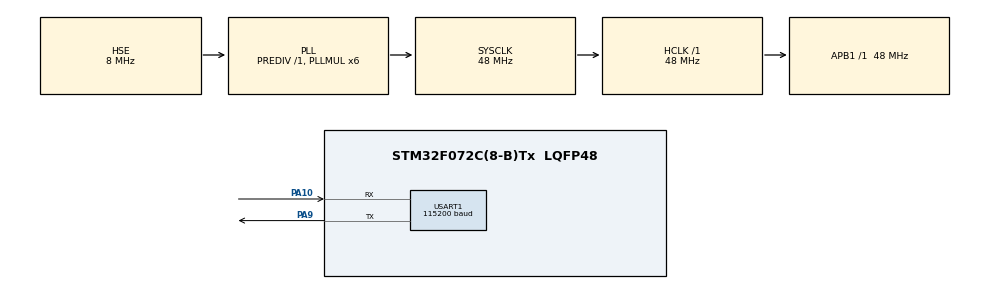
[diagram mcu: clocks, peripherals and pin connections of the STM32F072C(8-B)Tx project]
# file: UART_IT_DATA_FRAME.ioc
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Mcu.Family=STM32F0
Mcu.Name=STM32F072C(8-B)Tx
Mcu.Package=LQFP48
NVIC.USART1_IRQn=true\:0\:0\:false\:false\:true\:true\:true\:true
PA10.Mode=Asynchronous
PA10.Signal=USART1_RX
PA13.Mode=Serial_Wire
PA13.Signal=SYS_SWDIO
PA14.Mode=Serial_Wire
PA14.Signal=SYS_SWCLK
PA9.Mode=Asynchronous
PA9.Signal=USART1_TX
PF0-OSC_IN.Mode=HSE-External-Oscillator
PF0-OSC_IN.Signal=RCC_OSC_IN
PF1-OSC_OUT.Mode=HSE-External-Oscillator
PF1-OSC_OUT.Signal=RCC_OSC_OUT
ProjectManager.HeapSize=0x200
ProjectManager.StackSize=0x400
ProjectManager.TargetToolchain=MDK-ARM V5.32
RCC.AHBFreq_Value=48000000
RCC.APB1Freq_Value=48000000
RCC.APB1TimFreq_Value=48000000
RCC.HCLKFreq_Value=48000000
RCC.PLLMUL=RCC_PLL_MUL6
RCC.PLLSourceVirtual=RCC_PLLSOURCE_HSE
RCC.SYSCLKFreq_VALUE=48000000
RCC.SYSCLKSource=RCC_SYSCLKSOURCE_PLLCLK
USART1.BaudRate=115200
USART1.VirtualMode-Asynchronous=VM_ASYNC
board=custom

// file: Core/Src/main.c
/* USER CODE BEGIN Header */
/**
  ******************************************************************************
  * @file           : main.c
  * @brief          : Main program body
  ******************************************************************************
  * @attention
  *
  * Copyright (c) 2024 STMicroelectronics.
  * All rights reserved.
  *
  * This software is licensed under terms that can be found in the LICENSE file
  * in the root directory of this software component.
  * If no LICENSE file comes with this software, it is provided AS-IS.
  *
  ******************************************************************************
  */
/* USER CODE END Header */
#include "main.h"
#include "usart.h"
#include "gpio.h"

/* USER CODE BEGIN PV */
uint8_t uart_rx_buff[256];
uint8_t uart_tx_buff[256];
uint8_t recevie_byte = 0;
uint8_t receive_flag = 0;
uint8_t receive_index = 0;
/* USER CODE END PV */

void SystemClock_Config(void);

int main(void)
{

  /* MCU Configuration--------------------------------------------------------*/

  /* Reset of all peripherals, Initializes the Flash interface and the Systick. */
  HAL_Init();

  /* Configure the system clock */
  SystemClock_Config();

  /* Initialize all configured peripherals */
  MX_GPIO_Init();
  MX_USART1_UART_Init();
  /* USER CODE BEGIN 2 */
  HAL_UART_Receive_IT(&huart1,&recevie_byte,1);
  /* USER CODE END 2 */

  /* Infinite loop */
  /* USER CODE BEGIN WHILE */
  while (1)
  {
	  if(receive_flag == 1)
	  {
			uart_tx_buff[0] = 0x01;
			uart_tx_buff[1] = 0x06;
			uart_tx_buff[2] = 0x11;
			uart_tx_buff[3] = 0x00;
			uart_rx_buff[4] = 0xe9;
			uart_tx_buff[5] = 0xfe;
		  HAL_UART_Transmit(&huart1, uart_tx_buff, uart_tx_buff[1], 1000);
		  receive_flag = 0;
	  }
    /* USER CODE END WHILE */

  }
}

void SystemClock_Config(void)
{
  RCC_OscInitTypeDef RCC_OscInitStruct = {0};
  RCC_ClkInitTypeDef RCC_ClkInitStruct = {0};
  RCC_PeriphCLKInitTypeDef PeriphClkInit = {0};

  /** Initializes the RCC Oscillators according to the specified parameters
  * in the RCC_OscInitTypeDef structure.
  */
  RCC_OscInitStruct.OscillatorType = RCC_OSCILLATORTYPE_HSE;
  RCC_OscInitStruct.HSEState = RCC_HSE_ON;
  RCC_OscInitStruct.PLL.PLLState = RCC_PLL_ON;
  RCC_OscInitStruct.PLL.PLLSource = RCC_PLLSOURCE_HSE;
  RCC_OscInitStruct.PLL.PLLMUL = RCC_PLL_MUL6;
  RCC_OscInitStruct.PLL.PREDIV = RCC_PREDIV_DIV1;
  if (HAL_RCC_OscConfig(&RCC_OscInitStruct) != HAL_OK)
  {
    Error_Handler();
  }

  /** Initializes the CPU, AHB and APB buses clocks
  */
  RCC_ClkInitStruct.ClockType = RCC_CLOCKTYPE_HCLK|RCC_CLOCKTYPE_SYSCLK
                              |RCC_CLOCKTYPE_PCLK1;
  RCC_ClkInitStruct.SYSCLKSource = RCC_SYSCLKSOURCE_PLLCLK;
  RCC_ClkInitStruct.AHBCLKDivider = RCC_SYSCLK_DIV1;
  RCC_ClkInitStruct.APB1CLKDivider = RCC_HCLK_DIV1;

  if (HAL_RCC_ClockConfig(&RCC_ClkInitStruct, FLASH_LATENCY_1) != HAL_OK)
  {
    Error_Handler();
  }
  PeriphClkInit.PeriphClockSelection = RCC_PERIPHCLK_USART1;
  PeriphClkInit.Usart1ClockSelection = RCC_USART1CLKSOURCE_PCLK1;
  if (HAL_RCCEx_PeriphCLKConfig(&PeriphClkInit) != HAL_OK)
  {
    Error_Handler();
  }
}

/* USER CODE BEGIN 4 */
void HAL_UART_RxCpltCallback(UART_HandleTypeDef *huart)
{
	if(huart->Instance == USART1)
	{
		if(receive_flag == 0)
		{
			//串口数据填入缓冲区

			uart_rx_buff[receive_index] = recevie_byte;

			//确保第一个数据位FRAME_HEADER (帧头)
			if(uart_rx_buff[0] == 0x01 || receive_index > 0)
			{
				receive_index++;
			}
			else
			{
				receive_index = 0;
			}

			if(receive_index == uart_rx_buff[1]) // 验证数据包的长度
			{

				if(uart_rx_buff[receive_index - 1] == 0xfe)
				{
					receive_flag = 1;
				}
				receive_index = 0;
			}
		}
		HAL_UART_Receive_IT(&huart1, &recevie_byte, 1);
	}
}
/* USER CODE END 4 */

void Error_Handler(void)
{
  __disable_irq();
  while (1)
  {
  }
}
